# STM32GBK1CBT6 register map
File version: 1.2
CPU: CM4 r0p1, little endian, MPU, FPU, 4 interrupt priority bits
Registers are 32-bit, read-write, reset 0x0 unless marked. A register's access mark holds for its fields unless they carry their own. Offsets are from the block's base; [hi:lo] are bit positions; {n}, {i} and the like mark numbered series.

## GPIOA — General-purpose I/Os
Base 0x48000000
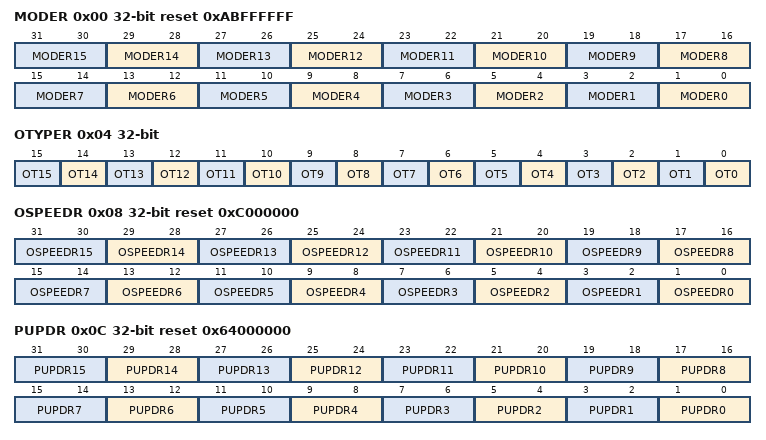
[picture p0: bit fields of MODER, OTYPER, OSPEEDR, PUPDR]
0x00 MODER reset 0xABFFFFFF — GPIO port mode register
  [2n+1:2n] MODER{n} (n=0..15) — Port x configuration bits (y = 0..15)
0x04 OTYPER — GPIO port output type register
  [n] OT{n} (n=0..15) — Port x configuration bits (y = 0..15)
0x08 OSPEEDR reset 0xC000000 — GPIO port output speed register
  [2n+1:2n] OSPEEDR{n} (n=0..15) — Port x configuration bits (y = 0..15)
0x0C PUPDR reset 0x64000000 — GPIO port pull-up/pull-down register
  [2n+1:2n] PUPDR{n} (n=0..15) — Port x configuration bits (y = 0..15)
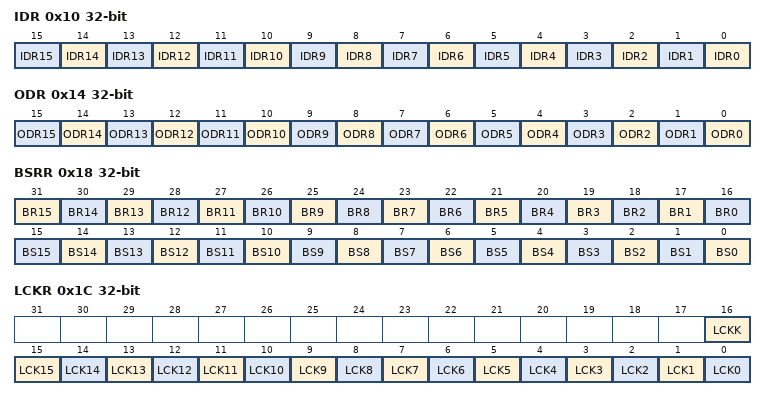
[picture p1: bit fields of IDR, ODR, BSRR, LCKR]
0x10 IDR ro — GPIO port input data register
  [n] IDR{n} (n=0..15) — Port input data (y = 0..15)
0x14 ODR — GPIO port output data register
  [n] ODR{n} (n=0..15) — Port output data (y = 0..15)
0x18 BSRR wo — GPIO port bit set/reset register
  [n+16] BR{n} (n=1..15) — Port x reset bit y (y = 0..15)
  [16] BR0 — Port x set bit y (y= 0..15)
  [n] BS{n} (n=0..15) — Port x set bit y (y= 0..15)
0x1C LCKR — GPIO port configuration lock register
  [16] LCKK — Port x lock bit y (y= 0..15)
  [n] LCK{n} (n=0..15) — Port x lock bit y (y= 0..15)
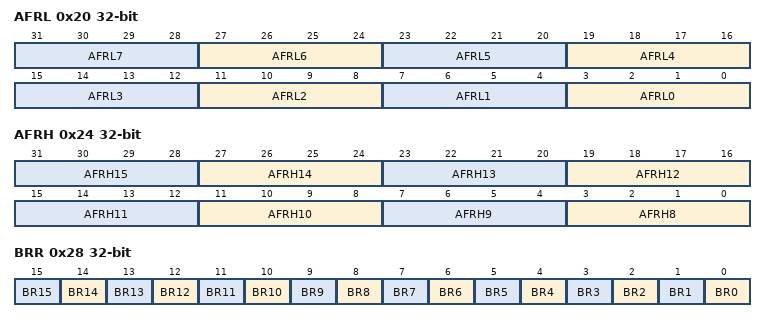
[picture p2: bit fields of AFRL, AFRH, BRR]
0x20 AFRL — GPIO alternate function low register
  [4n+3:4n] AFRL{n} (n=0..7) — Alternate function selection for port x bit y (y = 0..7)
0x24 AFRH — GPIO alternate function high register
  [4n-29:4n-32] AFRH{n} (n=8..15) — Alternate function selection for port x bit y (y = 8..15)
0x28 BRR wo — GPIO port bit reset register
  [n] BR{n} (n=0..15) — Port Reset bit

## GPIOB — General-purpose I/Os
Base 0x48000400
Registers as GPIOA; these are added or differ:
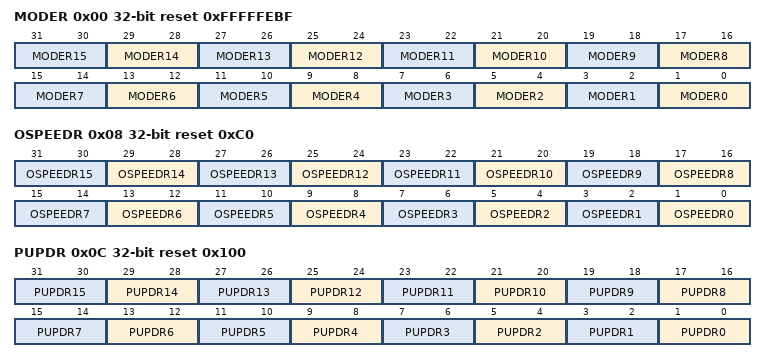
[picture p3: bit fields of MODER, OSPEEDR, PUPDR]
0x00 MODER reset 0xFFFFFEBF — GPIO port mode register
  [2n+1:2n] MODER{n} (n=0..15) — Port x configuration bits (y = 0..15)
0x08 OSPEEDR reset 0xC0 — GPIO port output speed register
  [2n+1:2n] OSPEEDR{n} (n=0..15) — Port x configuration bits (y = 0..15)
0x0C PUPDR reset 0x100 — GPIO port pull-up/pull-down register
  [2n+1:2n] PUPDR{n} (n=0..15) — Port x configuration bits (y = 0..15)

## GPIOC — General-purpose I/Os
Base 0x48000800
Same registers: GPIOD 0x48000C00, GPIOE 0x48001000, GPIOF 0x48001400, GPIOG 0x48001800
Registers as GPIOA; these are added or differ:
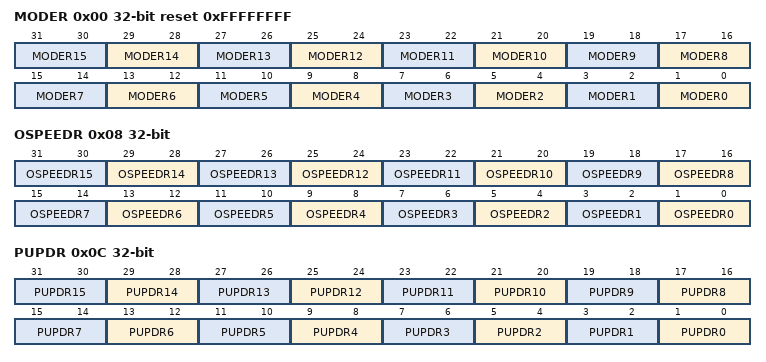
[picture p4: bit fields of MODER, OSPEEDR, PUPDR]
0x00 MODER reset 0xFFFFFFFF — GPIO port mode register
  [2n+1:2n] MODER{n} (n=0..15) — Port x configuration bits (y = 0..15)
0x08 OSPEEDR — GPIO port output speed register
  [2n+1:2n] OSPEEDR{n} (n=0..15) — Port x configuration bits (y = 0..15)
0x0C PUPDR — GPIO port pull-up/pull-down register
  [2n+1:2n] PUPDR{n} (n=0..15) — Port x configuration bits (y = 0..15)

## TIM16 — General purpose timers
Base 0x40014400
Same registers: TIM17 0x40014800
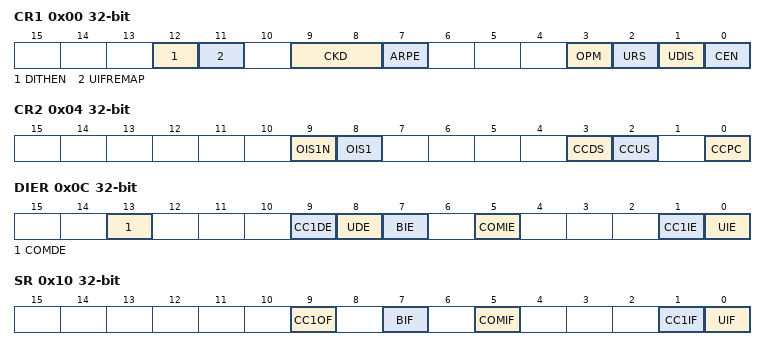
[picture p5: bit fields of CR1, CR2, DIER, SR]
0x00 CR1 — control register 1
  [12] DITHEN — Dithering Enable
  [11] UIFREMAP — UIF status bit remapping
  [9:8] CKD — Clock division
  [7] ARPE — Auto-reload preload enable
  [3] OPM — One-pulse mode
  [2] URS — Update request source
  [1] UDIS — Update disable
  [0] CEN — Counter enable
0x04 CR2 — control register 2
  [9] OIS1N — Output Idle state 1
  [8] OIS1 — Output Idle state 1
  [3] CCDS — Capture/compare DMA selection
  [2] CCUS — Capture/compare control update selection
  [0] CCPC — Capture/compare preloaded control
0x0C DIER — DMA/Interrupt enable register
  [13] COMDE — COM DMA request enable
  [9] CC1DE — Capture/Compare 1 DMA request enable
  [8] UDE — Update DMA request enable
  [7] BIE — Break interrupt enable
  [5] COMIE — COM interrupt enable
  [1] CC1IE — Capture/Compare 1 interrupt enable
  [0] UIE — Update interrupt enable
0x10 SR — status register
  [9] CC1OF — Capture/Compare 1 overcapture flag
  [7] BIF — Break interrupt flag
  [5] COMIF — COM interrupt flag
  [1] CC1IF — Capture/compare 1 interrupt flag
  [0] UIF — Update interrupt flag
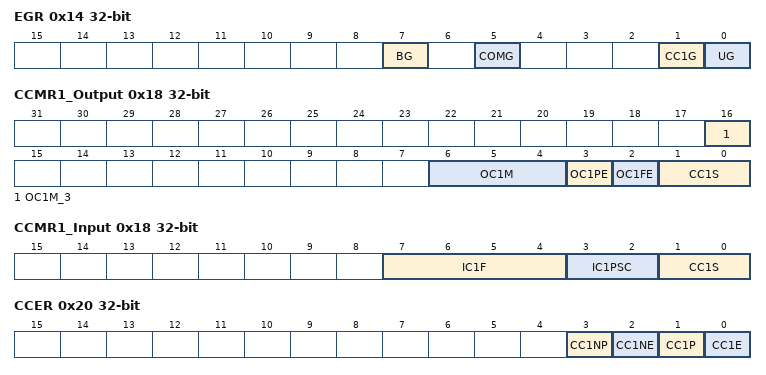
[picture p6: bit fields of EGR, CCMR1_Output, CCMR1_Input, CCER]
0x14 EGR wo — event generation register
  [7] BG — Break generation
  [5] COMG — Capture/Compare control update generation
  [1] CC1G — Capture/compare 1 generation
  [0] UG — Update generation
0x18 CCMR1_Output — capture/compare mode register (output mode)
  [16] OC1M_3 — Output Compare 1 mode
  [6:4] OC1M — Output Compare 1 mode
  [3] OC1PE — Output Compare 1 preload enable
  [2] OC1FE — Output Compare 1 fast enable
  [1:0] CC1S — Capture/Compare 1 selection
0x18 CCMR1_Input (alternate view of CCMR1_Output) — capture/compare mode register 1 (input mode)
  [7:4] IC1F — Input capture 1 filter
  [3:2] IC1PSC — Input capture 1 prescaler
  [1:0] CC1S — Capture/Compare 1 selection
0x20 CCER — capture/compare enable register
  [3] CC1NP — Capture/Compare 1 output Polarity
  [2] CC1NE — Capture/Compare 1 complementary output enable
  [1] CC1P — Capture/Compare 1 output Polarity
  [0] CC1E — Capture/Compare 1 output enable
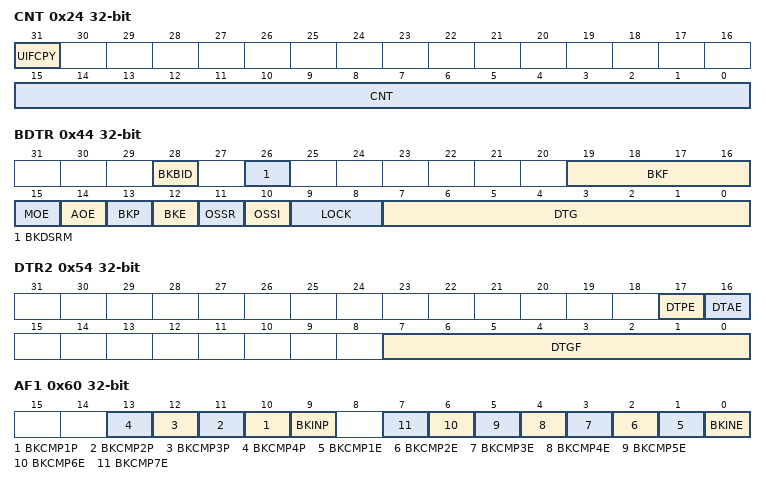
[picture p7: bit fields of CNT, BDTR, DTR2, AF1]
0x24 CNT access per field — counter
  [31] UIFCPY ro — UIF Copy
  [15:0] CNT rw — counter value
0x28 PSC — prescaler
  [15:0] PSC — Prescaler value
0x2C ARR reset 0xFFFF — auto-reload register
  [15:0] ARR — Auto-reload value
0x30 RCR — repetition counter register
  [7:0] REP — Repetition counter value
0x34 CCR1 — capture/compare register 1
  [15:0] CCR1 — Capture/Compare 1 value
0x44 BDTR — break and dead-time register
  [28] BKBID
  [26] BKDSRM
  [19:16] BKF — Break filter
  [15] MOE — Main output enable
  [14] AOE — Automatic output enable
  [13] BKP — Break polarity
  [12] BKE — Break enable
  [11] OSSR — Off-state selection for Run mode
  [10] OSSI — Off-state selection for Idle mode
  [9:8] LOCK — Lock configuration
  [7:0] DTG — Dead-time generator setup
0x54 DTR2 — timer Deadtime Register 2
  [17] DTPE — Deadtime Preload Enable
  [16] DTAE — Deadtime Asymmetric Enable
  [7:0] DTGF — Dead-time generator setup
0x5C TISEL — TIM timer input selection register
  [3:0] TI1SEL — TI1[0] to TI1[15] input selection
0x60 AF1 — TIM alternate function option register 1
  [n+9] BKCMP{n}P (n=1..4) — BRK COMP{n} input polarity
  [9] BKINP — BRK BKIN input polarity
  [n] BKCMP{n}E (n=1..7) — BRK COMP{n} enable
  [0] BKINE — BRK BKIN input enable
0x64 AF2 — TIM alternate function option register 2
  [18:16] OCRSEL — OCREF_CLR source selection
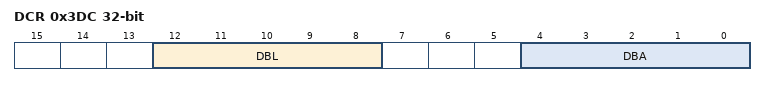
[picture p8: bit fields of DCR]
0x3DC DCR — DMA control register
  [12:8] DBL — DMA burst length
  [4:0] DBA — DMA base address
0x3E0 DMAR — DMA address for full transfer
  [31:0] DMAB — DMA register for burst accesses
